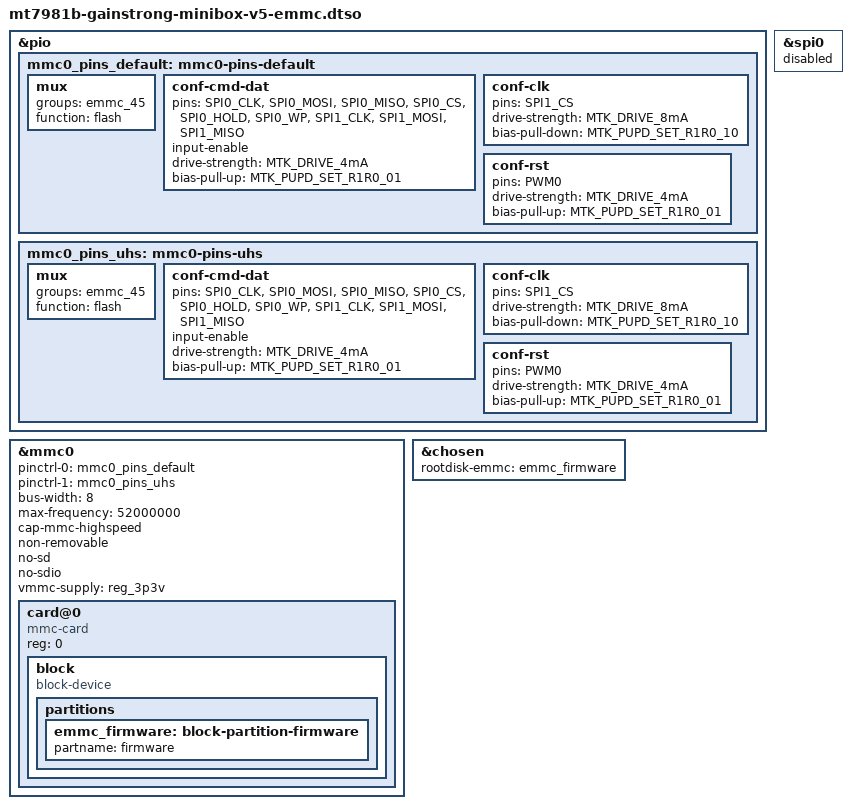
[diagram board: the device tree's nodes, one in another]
/* SPDX-License-Identifier: (GPL-2.0-only OR MIT) */
/dts-v1/;
/plugin/;

#include <dt-bindings/pinctrl/mt65xx.h>

&pio {
	mmc0_pins_default: mmc0-pins-default {
		mux {
			groups = "emmc_45";
			function = "flash";
		};
		conf-cmd-dat {
			pins = "SPI0_CLK", "SPI0_MOSI", "SPI0_MISO",
				"SPI0_CS", "SPI0_HOLD", "SPI0_WP",
				"SPI1_CLK", "SPI1_MOSI", "SPI1_MISO";
			input-enable;
			drive-strength = <MTK_DRIVE_4mA>;
			bias-pull-up = <MTK_PUPD_SET_R1R0_01>;
		};
		conf-clk {
			pins = "SPI1_CS";
			drive-strength = <MTK_DRIVE_8mA>;
			bias-pull-down = <MTK_PUPD_SET_R1R0_10>;
		};
		conf-rst {
			pins = "PWM0";
			drive-strength = <MTK_DRIVE_4mA>;
			bias-pull-up = <MTK_PUPD_SET_R1R0_01>;
		};
	};

	mmc0_pins_uhs: mmc0-pins-uhs {
		mux {
			groups = "emmc_45";
			function = "flash";
		};
		conf-cmd-dat {
			pins = "SPI0_CLK", "SPI0_MOSI", "SPI0_MISO",
				"SPI0_CS", "SPI0_HOLD", "SPI0_WP",
				"SPI1_CLK", "SPI1_MOSI", "SPI1_MISO";
			input-enable;
			drive-strength = <MTK_DRIVE_4mA>;
			bias-pull-up = <MTK_PUPD_SET_R1R0_01>;
		};
		conf-clk {
			pins = "SPI1_CS";
			drive-strength = <MTK_DRIVE_8mA>;
			bias-pull-down = <MTK_PUPD_SET_R1R0_10>;
		};
		conf-rst {
			pins = "PWM0";
			drive-strength = <MTK_DRIVE_4mA>;
			bias-pull-up = <MTK_PUPD_SET_R1R0_01>;
		};
	};
};

&mmc0 {
	pinctrl-names = "default", "state_uhs";
	pinctrl-0 = <&mmc0_pins_default>;
	pinctrl-1 = <&mmc0_pins_uhs>;
	bus-width = <8>;
	max-frequency = <52000000>;
	cap-mmc-highspeed;
	non-removable;
	no-sd;
	no-sdio;
	vmmc-supply = <&reg_3p3v>;
	status = "okay";
	#address-cells = <1>;
	#size-cells = <0>;

	card@0 {
		compatible = "mmc-card";
		reg = <0>;

		block {
			compatible = "block-device";
			partitions {
				emmc_firmware: block-partition-firmware {
					partname = "firmware";
				};
			};
		};
	};
};

&chosen {
	rootdisk-emmc = <&emmc_firmware>;
};

&spi0 {
	status = "disabled";
};
